# PRU_ICSSG0_PR1_MII_RT_PR1_MII_RT_G_CFG_REGS_G_local register map
Vendor: Texas Instruments
Peripheral module from a debugger description file (folder am65x).
Registers are 32-bit, read-write, reset 0x0 unless marked. A register's access mark holds for its fields unless they carry their own. Offsets are as the file gives them; lines under a group give offsets from that group; [hi:lo] are bit positions; {n}, {i} and the like mark numbered series; 'fields as' and 'values as' point back to an identical list; <NAME> marks a mode.

## PRU_ICSSG0_PR1_MII_RT_PR1_MII_RT_G_CFG_REGS_G
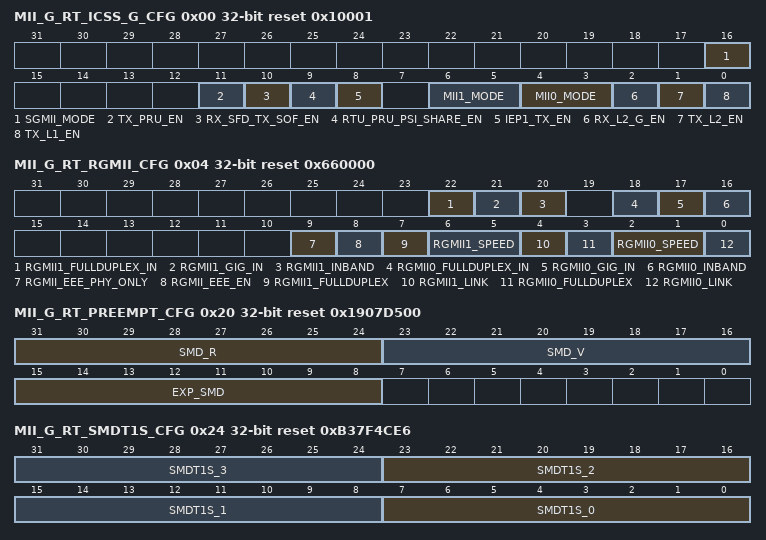
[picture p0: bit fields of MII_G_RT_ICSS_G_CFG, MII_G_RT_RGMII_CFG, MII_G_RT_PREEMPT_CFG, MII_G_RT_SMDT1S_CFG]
0x00 MII_G_RT_ICSS_G_CFG reset 0x10001 — ICSS_G Config
  [16] SGMII_MODE — SGMII MODE 0: Fiber MODE 1: SGMII MODE
  [11] TX_PRU_EN — Enable TX_PRU to gain control of MII TXL2
  [10] RX_SFD_TX_SOF_EN — Enable the remaping of tx_sof to rx_sfd if auto fwd is enable
  [9] RTU_PRU_PSI_SHARE_EN — Enable the sharing of xfr2psi attached to PRU for PRU RTU AND HW FIFO
  [8] IEP1_TX_EN — Enable IEP1 for TX Enable 0: Use IEP0 CMP3_4 1: Use IEP1 CMP3_4
  [6:5] MII1_MODE — MII1 MODE 0: MII 1: RGMII 2: SGMII
  [4:3] MII0_MODE — MII0 MODE 0: MII 1: RGMII 2: SGMII
  [2] RX_L2_G_EN — Enable new RX L2 mode of operation for non-EtherCAT Slave protocols. 0: Disabled 1: Enabled Disable for EtherCAT Slave protocols, enable for all other protocols.
  [1] TX_L2_EN — Enable the TX L2 Fifo 0: Disabled 1: Enabled
  [0] TX_L1_EN — Enable the TX L1 Fifo 0: Disabled 1: Enabled
0x04 MII_G_RT_RGMII_CFG access per field reset 0x660000 — RGMII
  [22] RGMII1_FULLDUPLEX_IN rw — RGMII Fullduplex overide 0: half 1: full
  [21] RGMII1_GIG_IN rw — RGMII GigBit Enable 0: 100 Mbs 1: 1000 Mbs
  [20] RGMII1_INBAND rw — RGMII In BandEnable or Force 0: InBAND is Disabled 1: InBAND Enable
  [18] RGMII0_FULLDUPLEX_IN rw — RGMII Fullduplex overide 0: half 1: full
  [17] RGMII0_GIG_IN rw — RGMII GigBit Enable 0: 100 Mbs 1: 1000 Mbs
  [16] RGMII0_INBAND rw — RGMII In BandEnable or Force 0: InBAND is Disabled 1: InBAND Enable
  [9] RGMII_EEE_PHY_ONLY rw — RGMII Phy Only Low Power 0: disable 1: enable
  [8] RGMII_EEE_EN rw — RGMII Energy Efficient Enable 0: disable 1: enable
  [7] RGMII1_FULLDUPLEX ro — RGMII Fullduplex 0: half duplex 1: full duplex
  [6:5] RGMII1_SPEED ro — RGMII Speed 00: 10Mpbs 01: 100Mpbs 10: 1000 Mpbs
  [4] RGMII1_LINK ro — RGMII Link Status 0: link is down 1: link is up
  [3] RGMII0_FULLDUPLEX ro — RGMII Fullduplex 0: half duplex 1: full duplex
  [2:1] RGMII0_SPEED ro — RGMII Speed 00: 10Mpbs 01: 100Mpbs 10: 1000 Mpbs
  [0] RGMII0_LINK ro — RGMII Link Status 0: link is down 1: link is up
0x08 MII_G_RT_MAC_PRU0_0 — PRU0 MAC (DA3:DA0).
  [31:0] MAC_PRU0_0 — MAC PRU0 DA3:DA0 Used for SAV and DA match
0x0C MII_G_RT_MAC_PRU0_1 — PRU0 MAC (DA5:DA4).
  [15:0] MAC_PRU0_1 — MAC PRU0 DA5:DA4 Used for SAV and DA match
0x10 MII_G_RT_MAC_PRU1_0 — PRU1 MAC (DA3:DA0).
  [31:0] MAC_PRU1_0 — MAC PRU1 DA3:DA0 Used for SAV and DA match
0x14 MII_G_RT_MAC_PRU1_1 — PRU1 MAC (DA5:DA4).
  [15:0] MAC_PRU1_1 — MAC PRU1 DA5:DA4 Used for SAV and DA match
0x18 MII_G_RT_MAC_INTERFACE_0 — MAC Host Interface (DA3:DA0).
  [31:0] MAC_INF_0 — MAC Host interface DA3:DA0 Used for SAV and DA match
0x1C MII_G_RT_MAC_INTERFACE_1 — MAC Host Interface (DA5:DA4).
  [15:0] MAC_INF_1 — MAC Host interface DA 5:DA4 Used for SAV and DA match
0x20 MII_G_RT_PREEMPT_CFG reset 0x1907D500 — Preempt Configuration Register.
  [31:24] SMD_R — Response frame TAG
  [23:16] SMD_V — Verification frame TAG
  [15:8] EXP_SMD — None preemptable frame start, or express frame
0x24 MII_G_RT_SMDT1S_CFG reset 0xB37F4CE6 — SMD Type1S Preemptable Frame Start Configuration.
  [8n+7:8n] SMDT1S_{n} (n=0..3) — SMDT1S{n} pattern
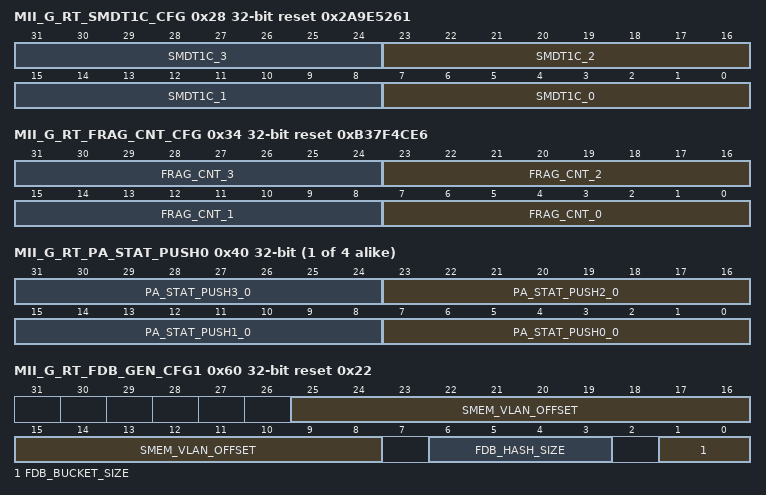
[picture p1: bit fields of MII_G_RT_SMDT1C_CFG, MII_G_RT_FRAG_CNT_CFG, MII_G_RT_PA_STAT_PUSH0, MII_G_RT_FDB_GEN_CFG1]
0x28 MII_G_RT_SMDT1C_CFG reset 0x2A9E5261 — SMD Type1C None Initial Frag Configuration.
  [8n+7:8n] SMDT1C_{n} (n=0..3) — SMDT1C{n} pattern
0x34 MII_G_RT_FRAG_CNT_CFG reset 0xB37F4CE6 — Frag Count Configuration.
  [8n+7:8n] FRAG_CNT_{n} (n=0..3) — FRAG Cnt{n} pattern
{0x40+4i} MII_G_RT_PA_STAT_PUSH{i} (i=0..3) — Pa Stat Push{i}.
  [8n+7:8n] PA_STAT_PUSH{n}_{i} (n=0..3) — pa stat push{n}
0x60 MII_G_RT_FDB_GEN_CFG1 reset 0x22 — FDB Configuration1.
  [25:8] SMEM_VLAN_OFFSET — SMEM VLAN FID table base address
  [6:3] FDB_HASH_SIZE — FDB hash size 0:64 1:128 2:256 3:512 4:1024 5:2048
  [1:0] FDB_BUCKET_SIZE — FDB buket size 0:1 1:2 2:4 3:8
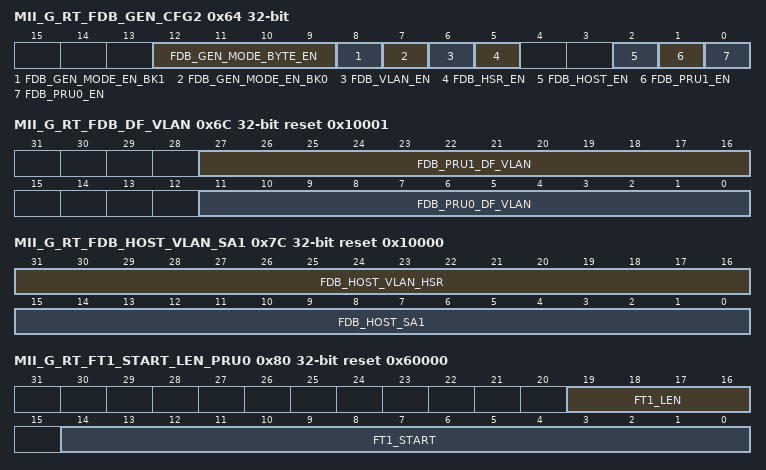
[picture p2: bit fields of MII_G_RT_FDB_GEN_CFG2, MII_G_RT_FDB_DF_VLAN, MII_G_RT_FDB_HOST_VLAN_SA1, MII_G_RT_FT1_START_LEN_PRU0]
0x64 MII_G_RT_FDB_GEN_CFG2 — FDB Configuration2.
  [12:9] FDB_GEN_MODE_BYTE_EN — FDB General Mode Byte compare size 0 = 1 Byte, 15 = 16 Bytes
  [8] FDB_GEN_MODE_EN_BK1 — FDB General Mode Enable Bank1 if set PRU0/PRU1/HOST will get disabled
  [7] FDB_GEN_MODE_EN_BK0 — FDB General Mode Enable Bank0 if set PRU0/PRU1/HOST will get disabled
  [6] FDB_VLAN_EN — FDB Global VLAN Enable
  [5] FDB_HSR_EN — FDB Global HSR Enable note VLAN most be disabled
  [2] FDB_HOST_EN — FDB HOST Enable
  [1] FDB_PRU1_EN — FDB PRU1 Enable
  [0] FDB_PRU0_EN — FDB PRU0 Enable
0x68 MII_G_RT_FDB_GEN_STATUS size not given access not given reset not defined — FDB Status.
0x6C MII_G_RT_FDB_DF_VLAN reset 0x10001 — FDB Default PRU VLAN.
  [27:16] FDB_PRU1_DF_VLAN — FDB Default VLAN for PRU1
  [11:0] FDB_PRU0_DF_VLAN — FDB Default VLAN for PRU0
0x70 MII_G_RT_FDB_HOST_DA0 — FDB HOST DA3:0 Configuration.
  [31:0] FDB_HOST_DA0 — FDB HOST DA3:0
0x74 MII_G_RT_FDB_HOST_DA1 — FDB HOST DA5:4 Configuration.
  [15:0] FDB_HOST_DA1 — FDB HOST DA 5:4
0x78 MII_G_RT_FDB_HOST_SA0 — FDB HOST SA3:0 Configuration.
  [31:0] FDB_HOST_SA0 — FDB HOST SA3:0
0x7C MII_G_RT_FDB_HOST_VLAN_SA1 reset 0x10000 — FDB HOST VLAN SA5:4 Configuration.
  [31:16] FDB_HOST_VLAN_HSR — FDB HOST VLAN[11:0] OR HSR [15:0]
  [15:0] FDB_HOST_SA1 — FDB HOST SA 5:4
0x80 MII_G_RT_FT1_START_LEN_PRU0 reset 0x60000 — Filter1 Start and Length (PRU0).
  [19:16] FT1_LEN — Defines the total number of Bytes Filter1 will check before Valid bit is set
  [14:0] FT1_START — Byte count start for Filter1. Any wrt will clear all Filter1 Status Bits
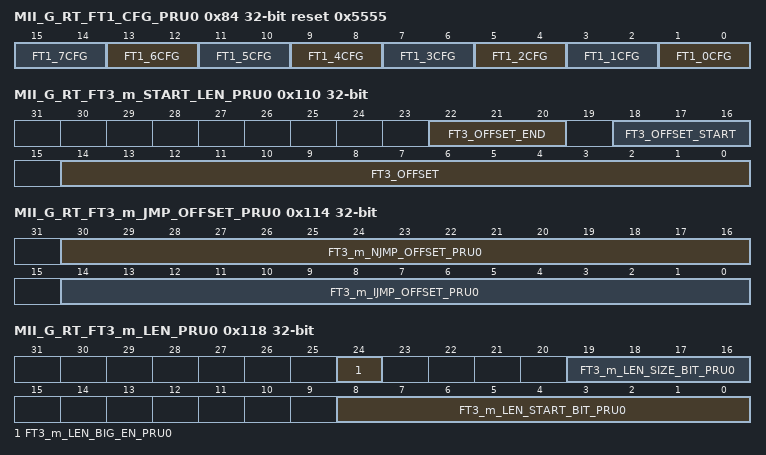
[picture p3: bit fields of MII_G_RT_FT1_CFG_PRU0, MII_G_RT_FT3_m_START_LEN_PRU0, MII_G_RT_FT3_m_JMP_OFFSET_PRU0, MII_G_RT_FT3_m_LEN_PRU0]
0x84 MII_G_RT_FT1_CFG_PRU0 reset 0x5555 — Filter1 Configuration (PRU0).
  [2n+1:2n] FT1_{n}CFG (n=0..7) — 0h = Disabled 1h = Equal 2h = Greater Than 3h = Less Than
0x88 MII_G_RT_FT1_k_DA0_PRU0 — Filter1<k> DA0 (Pru0). Offset = 88h + (k * 10h); where k = 0h to 7h
  [31:0] FT1_k_DA0 — Filter1 DA4:DA1
0x8C MII_G_RT_FT1_k_DA1_PRU0 — Filter1<k> DA1 (PRU0). Offset = 8Ch + (k * 10h); where k = 0h to 7h
  [15:0] FT1_k_DA1 — Filter1 DA6:DA5
0x90 MII_G_RT_FT1_k_DA_MASK0_PRU0 — Filter1<k> DA0 Mask (PRU0). Offset = 90h + (k * 10h); where k = 0h to 7h
  [31:0] FT1_k_DA_MASK0 — Filter1 MDA4:MDA1 set to 1 to mask that bit
0x94 MII_G_RT_FT1_k_DA_MASK1_PRU0 — Filter1<k> DA1 Mask (PRU0). Offset = 94h + (k * 10h); where k = 0h to 7h
  [15:0] FT1_k_DA_MASK1 — Filter1 MDA6:MDA5 set to 1 to mask that bit
0x108 MII_G_RT_FT3_m_START_PRU0 reset 0xC — Filter3 Byte Count Start. Offset = 108h + (m * 20h); where m = 0h to Fh
  [14:0] FT3_START — Byte count start for Filter3. Any wrt will clear all Filter3 Status Bits SW can read to determine next start during Auto
0x10C MII_G_RT_FT3_m_START_AUTO_PRU0 ro — Filter3 Byte Count Start for Auto Skip mode. Offset = 10Ch + (m * 20h); where m = 0h to Fh
  [14:0] FT3_START_AUTO — Byte count start for Auto skip mode
0x110 MII_G_RT_FT3_m_START_LEN_PRU0 — Filter3 Start Offset for PRU0. Offset = 110h + (m * 20h); where m = 0h to Fh
  [22:20] FT3_OFFSET_END — Defines which byte within FT3_[N]P[63:0] to end the compare at set the Valid flag, rule ft3_offset_end &gt;= ft3_offset_start To disable pattern compare set start and end to zero
  [18:16] FT3_OFFSET_START — Defines which byte within FT3_[N]P[63:0] to start the compare
  [14:0] FT3_OFFSET — Determine which byte to start FT3_[N]P[63:0] operation it will start on the next byte after FT3_T completes if set to zero
0x114 MII_G_RT_FT3_m_JMP_OFFSET_PRU0 — Filter3 Jump Offset for PRU0. Offset = 114h + (m * 20h); where m = 0h to Fh
  [30:16] FT3_m_NJMP_OFFSET_PRU0 — Defines the Next Offset to compare when auto arm jump is enabled
  [14:0] FT3_m_IJMP_OFFSET_PRU0 — Defines the Intial Offset to compare when auto arm jump is enabled
0x118 MII_G_RT_FT3_m_LEN_PRU0 — Filter3 Length Offset for PRU0. Offset = 118h + (m * 20h); where m = 0h to Fh
  [24] FT3_m_LEN_BIG_EN_PRU0 — Enable Big Indian on Length
  [19:16] FT3_m_LEN_SIZE_BIT_PRU0 — Defines number of bits to extract the length for the auto skip function
  [8:0] FT3_m_LEN_START_BIT_PRU0 — Defines relative bit offset from the HIT byte location upto 512 bit offset the exraction to determine the on the fly length byte offset
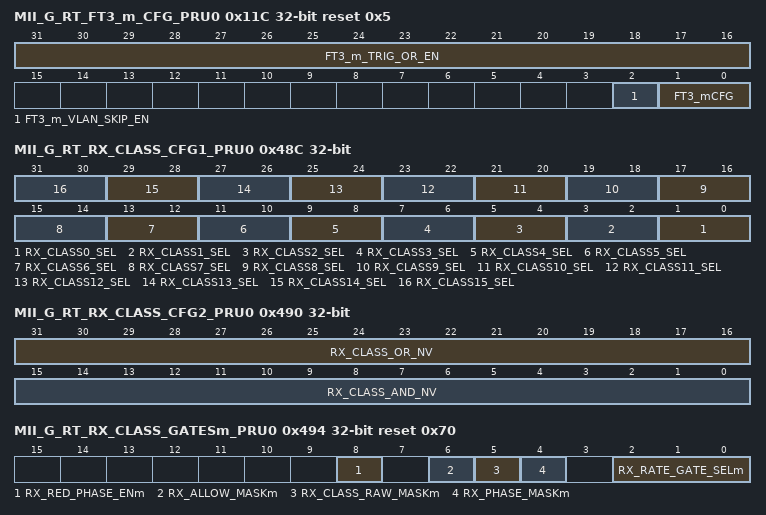
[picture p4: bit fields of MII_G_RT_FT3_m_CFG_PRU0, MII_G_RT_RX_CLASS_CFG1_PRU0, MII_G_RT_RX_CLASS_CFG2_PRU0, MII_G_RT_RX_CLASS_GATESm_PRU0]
0x11C MII_G_RT_FT3_m_CFG_PRU0 reset 0x5 — Filter3 Configuration for PRU0. Offset = 11Ch + (m * 20h); where m = 0h to Fh
  [31:16] FT3_m_TRIG_OR_EN — Trigger ft3 select for auto skip enable, if one or more set the function is enabled note you can not slect the same ft3 only others
  [2] FT3_m_VLAN_SKIP_EN — 0: Disabled 1: Enable
  [1:0] FT3_mCFG — 0: Disabled 1: EQ 2: GT 3: LT
0x120 MII_G_RT_FT3_m_T_PRU0 — Filter3 Type for PRU0. Offset = 120h + (m * 20h); where m = 0h to Fh
  [31:0] FT3_m_T — Filter3 T4:T1 Note if Auto Skip is enabled then Type filter is not enabled
0x124 MII_G_RT_FT3_m_T_MASK_PRU0 — Filter3 Mask for PRU0. Offset = 124h + (m * 20h); where m = 0h to Fh
  [31:0] FT3_m_T_MASK — Filter3 MT4:MT1 Note if Auto Skip is enabled then Type filter is not enabled set to 1 to mask that bit
0x308 MII_G_RT_FT3_m_P0_PRU0 — Filter3 PRU0 (P4:P1). Offset = 308h + (m * 10h); where m = 0h to Fh
  [31:0] FT3_m_P0 — Filter3 P4:P1
0x30C MII_G_RT_FT3_m_P1_PRU0 — Filter3 PRU0 (P8:P5). Offset = 30Ch + (m * 10h); where m = 0h to Fh
  [31:0] FT3_m_P1 — Filter3 P8:P5
0x310 MII_G_RT_FT3_n_P_MASK0_PRU0 — Filter3 Mask0 (MP4:MP1). Offset = 310h + (n * 10h); where n = 0h to Fh
  [31:0] FT3_n_P_MASK0 — Filter3 MP4:MP1 set to 1 to mask that bit
0x314 MII_G_RT_FT3_n_P_MASK1_PRU0 — Filter3 Mask1 (MP8:MP5). Offset = 314h + (n * 10h); where n = 0h to Fh
  [31:0] FT3_n_P_MASK1 — Filter3 MP8:MP5 set to 1 to mask that bit
0x408 MII_G_RT_FT_RX_PTR_PRU0 — RX Current Filter Byte Count (PRU0).
  [31:0] FT_RX_PTR_PRU0 — RX current filter Byte Count
0x40C MII_G_RT_RX_CLASSm_AND_EN_PRU0 — RX Class<m> AND Enable Register. Offset = 40Ch + (m * 8h); where m = 0h to Fh
  [31:0] RX_CLASSm_AND_EN — rx class and enabels
0x410 MII_G_RT_RX_CLASSm_OR_EN_PRU0 — RX Class<m> OR Enable Register. Offset = 410h + (m * 8h); where m = 0h to Fh
  [31:0] RX_CLASSm_OR_EN — rx class or enabels
0x48C MII_G_RT_RX_CLASS_CFG1_PRU0 — RX Class Configuration 1 Register.
  [2n+1:2n] RX_CLASS{n}_SEL (n=0..15) — rx class final term selection 00: OR 01: AND 10: OR AND AND OR 11: OR OR AND
0x490 MII_G_RT_RX_CLASS_CFG2_PRU0 — RX Class Configuration 2 Register.
  [31:16] RX_CLASS_OR_NV — RX class invert OR not invert enable
  [15:0] RX_CLASS_AND_NV — RX class invert AND not invert enable
0x494 MII_G_RT_RX_CLASS_GATESm_PRU0 reset 0x70 — RX Class Gate<m> Configuration PRU0 Register. Offset = 494h + (m * 4h); where m = 0h to Fh
  [8] RX_RED_PHASE_ENm — red phase neable 0: disable 1: enable
  [6] RX_ALLOW_MASKm — allow mask 0: unmask 1: mask
  [5] RX_CLASS_RAW_MASKm — class raw mask 0: unmask 1: mask
  [4] RX_PHASE_MASKm — time phase mask 0: unmask 1: mask
  [2:0] RX_RATE_GATE_SELm — defines which rx_rate will gate rx_class
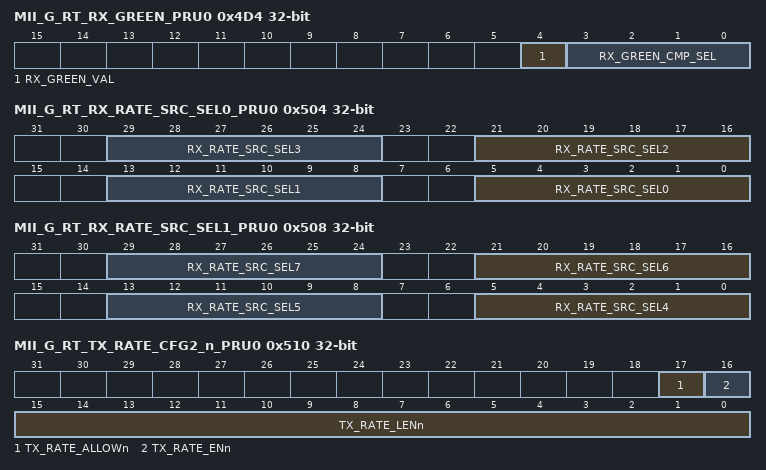
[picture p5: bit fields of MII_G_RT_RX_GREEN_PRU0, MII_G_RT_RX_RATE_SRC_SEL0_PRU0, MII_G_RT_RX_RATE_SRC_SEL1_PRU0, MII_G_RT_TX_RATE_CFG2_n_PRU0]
0x4D4 MII_G_RT_RX_GREEN_PRU0 access per field — RX Green Status PRU0.
  [4] RX_GREEN_VAL ro — 0 RED 1 GREEN status
  [3:0] RX_GREEN_CMP_SEL rw — define which IEP CMP start green
0x4D8 MII_G_RT_SA_HASH_PRU0 — SA Hash Seed PRU0.
  [9:0] SA_HASH_SEED
0x4DC MII_G_RT_CONN_HASH_PRU0 — Connection Hash Seed PRU0.
  [9:0] CONN_HASH_SEED — Connection Hash Seed
0x4E0 MII_G_RT_CONN_HASH_START_PRU0 — Connection Hash Start PRU0.
  [14:0] CONN_HASH_START — Connection Hash Start which 4 Bytes to hash
0x4E4 MII_G_RT_RX_RATE_CFGn_PRU0 — RX Rate Configuration<n> Register. Offset = 4E4h + (n * 4h); where n = 0h to 7h
  [31:0] RX_RATE_CIR_IDLEn — RX Rate Peak Information Rate Idle Increment Value - The number added to the PIR counter every clock cycle including EOF. The PIR counter is disabled with a zero value and packets will not be marked RED
0x504 MII_G_RT_RX_RATE_SRC_SEL0_PRU0 — RX Rate Source Select0.
  [8n+5:8n] RX_RATE_SRC_SEL{n} (n=0..3) — Map which filter/flag/class hit that rate logic uses, see table for mapping
0x508 MII_G_RT_RX_RATE_SRC_SEL1_PRU0 — RX Rate Source Select1.
  [8n-27:8n-32] RX_RATE_SRC_SEL{n} (n=4..7) — Map which filter/flag/class hit that rate logic uses, see table for mapping
0x50C MII_G_RT_TX_RATE_CFG1_n_PRU0 — TX Rate Configuration1 Registe. Offset = 50Ch + (n * 8h); where n = 0h to 7h
  [31:0] TX_RATE_CIR_IDLEn — TX Rate Peak Information Rate Idle Increment Value - The number added to the PIR counter every clock cycle including EOF. The PIR counter is disabled with a zero value and packets will not be marked RED
0x510 MII_G_RT_TX_RATE_CFG2_n_PRU0 access per field — TX Rate Configuration2 Register. Offset = 510h + (n * 8h); where n = 0h to 7h
  [17] TX_RATE_ALLOWn ro — TX Rate Pkt Enable
  [16] TX_RATE_ENn rw — TX Rate Pkt Enable
  [15:0] TX_RATE_LENn rw — TX Rate Pkt Length
0x54C MII_G_RT_RX_STAT_GOOD_PRU0 — RX Good Frame Count (PRU0).
  [31:0] RX_GOOD_FRM_CNT — RX Good Frame Count Inc on none min err max err crc err odd err, Wrt subtracts
0x550 MII_G_RT_RX_STAT_BC_PRU0 — RX BC Frame Count (PRU0).
  [15:0] RX_BC_FRM_CNT — RX BC Frame Count Inc on BC type, Wrt subtracts
0x554 MII_G_RT_RX_STAT_MC_PRU0 — RX MC Frame Count (PRU0).
  [15:0] RX_MC_FRM_CNT — RX MC Frame Count Inc on MC type, Wrt subtracts
0x558 MII_G_RT_RX_STAT_CRC_ERR_PRU0 — RX CRC Error Frame Count (PRU0).
  [15:0] RX_CRC_ERR_FRM_CNT — RX CRC Err Frame Count Inc on crc err, Wrt subtracts
0x55C MII_G_RT_RX_STAT_MII_ERR_PRU0 — RX MII Error Frame Count (PRU0).
  [15:0] RX_MII_ERR_FRM_CNT — RX MII Err Frame Count Inc on mii sgmii rgmii err, Wrt subtracts
0x560 MII_G_RT_RX_STAT_ODD_ERR_PRU0 — RX Odd Nibble Frame Count (PRU0).
  [15:0] RX_ODD_ERR_FRM_CNT — RX Odd Nibble Frame Count Inc on odd nibble mii, Wrt subtracts
0x564 MII_G_RT_RX_STAT_MAX_SIZE_PRU0 reset 0x7D0 — RX Max Size Frame Count (PRU0).
  [15:0] RX_MAX_SIZE_FRM — RX MAX Size Frame Count Limit
0x568 MII_G_RT_RX_STAT_MAX_ERR_PRU0 — RX Max Size Error Frame Count (PRU0).
  [15:0] RX_MAX_ERR_FRM_CNT — RX MAX Size Err Frame Count Inc if &gt; than Limit, Wrt subtracts
0x56C MII_G_RT_RX_STAT_MIN_SIZE_PRU0 reset 0x40 — RX Min Size Frame Count (PRU0).
  [15:0] RX_MIN_SIZE_FRM — RX MIN Size Frame Limit
0x570 MII_G_RT_RX_STAT_MIN_ERR_PRU0 — RX Min Size Error Frame Count (PRU0).
  [15:0] RX_MIN_ERR_FRM_CNT — RX MIN Size Frame Count Inc if &lt; than limit, Wrt subtracts
0x574 MII_G_RT_RX_STAT_OVERRUN_ERR_PRU0 — RX Overrun Frame Count (PRU0).
  [15:0] RX_OVERRUN_ERR_FRM_CNT — RX L1 FIFO overflow Frame Count. Inc on overflow event, Wrt subtracts
0x578 MII_G_RT_RX_STAT_CLASSm_HIT_PRU0 — RX Class<m> Hit. Offset = 578h + (n * 4h); where m = 0h to Fh
  [31:0] RX_STAT_CLASSm_PRU0 — RX Class&lt;m&gt; Hit Count (where m = 0 to 15). Wrt subtracts
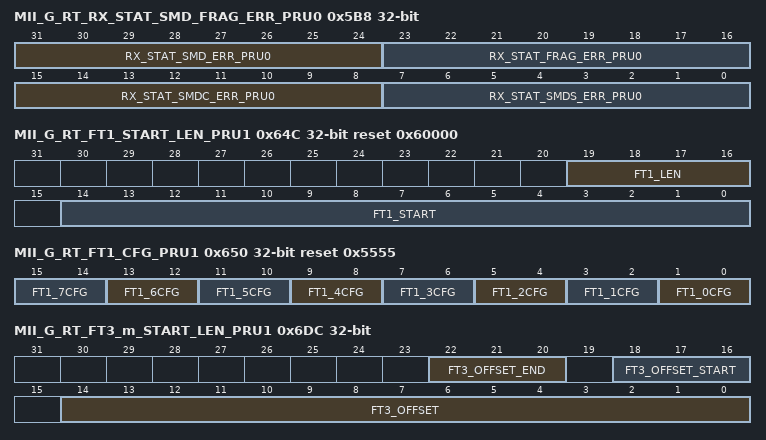
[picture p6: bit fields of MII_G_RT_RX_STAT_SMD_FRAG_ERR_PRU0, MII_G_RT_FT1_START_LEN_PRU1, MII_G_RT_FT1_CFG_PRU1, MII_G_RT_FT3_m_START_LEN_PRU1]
0x5B8 MII_G_RT_RX_STAT_SMD_FRAG_ERR_PRU0 — RX SMD Frag Error Count PRU0.
  [31:24] RX_STAT_SMD_ERR_PRU0 — RX SMDS Error Count, Inc when first none 0x55 does not match any valid SMD, Wrt subtracts
  [23:16] RX_STAT_FRAG_ERR_PRU0 — RX Frag_Cnt Seq Error Count, Wrt subtracts
  [15:8] RX_STAT_SMDC_ERR_PRU0 — RX SMDCx Seq Error Count, Wrt subtracts
  [7:0] RX_STAT_SMDS_ERR_PRU0 — RX SMDSx Seq Error Count, Wrt subtracts
0x5BC MII_G_RT_RX_STAT_BKT1_SIZE_PRU0 reset 0x40 — RX Bucket1 Size Configuration (PRU0).
  [13:0] RX_STAT_BKT1_SIZE — RX Bucket1 Byte Size
0x5C0 MII_G_RT_RX_STAT_BKT2_SIZE_PRU0 reset 0x80 — RX Bucket2 Size Configuration (PRU0).
  [13:0] RX_STAT_BKT2_SIZE — RX Bucket2 Byte Size
0x5C4 MII_G_RT_RX_STAT_BKT3_SIZE_PRU0 reset 0x100 — RX Bucket3 Size Configuration (PRU0).
  [13:0] RX_STAT_BKT3_SIZE — RX Bucket3 Byte Size
0x5C8 MII_G_RT_RX_STAT_BKT4_SIZE_PRU0 reset 0x200 — RX Bucket4 Size Configuration (PRU0).
  [13:0] RX_STAT_BKT4_SIZE — RX Bucket4 Byte Size
0x5CC MII_G_RT_RX_STAT_64_PRU0 — RX 64B Sized Frame Count (PRU0).
  [15:0] RX_64_FRM_CNT — RX 64Byte Frame Count Inc if 64B size
0x5D0 MII_G_RT_RX_STAT_BKT1_PRU0 — RX Bucket1 Sized Frame Count (PRU0).
  [15:0] RX_STAT_BKT1 — RX Bucket1 Frame Count Inc if &lt;= than Bucket1 Byte Size
{0x5CC+4i} MII_G_RT_RX_STAT_BKT{i}_PRU0 (i=2..4) — RX Bucket{i} Sized Frame Count (PRU0).
  [15:0] RX_STAT_BKT{i} — RX Bucket{i} Frame Count Inc if &lt;= than Bucket{i} Byte Size and if &gt; than Bucket{i-1} Byte Size
0x5E0 MII_G_RT_RX_STAT_BKT5_PRU0 — RX Bucket5 Sized Frame Count (PRU0).
  [15:0] RX_STAT_BKT5 — RX Bucket5 Frame Count Inc if &gt; than Bucket4 Byte Size
0x5E4 MII_G_RT_RX_STAT_TOTAL_BYTES_PRU0 — RX Total Byte Count (PRU0).
  [31:0] RX_STAT_TOTAL_BYTES_PRU — RX Total Byte Count
0x5E8 MII_G_RT_RXTX_STAT_TOTAL_BYTES_PRU0 — RX TX Total Byte Count (PRU0).
  [31:0] RXTX_STAT_TOTAL_BYTES_PRU — RX and TX Total Byte Count
0x5EC MII_G_RT_TX_STAT_GOOD_PORT0 — TX Good Frame Count Port0.
  [31:0] TX_GOOD_FRM_CNT — TX Good Frame Count Inc if no min size err max size err or mii odd nibble
0x5F0 MII_G_RT_TX_STAT_BC_PORT0 — TX BC Frame Count Port0.
  [15:0] TX_BC_FRM_CNT — TX BC Frame Count Inc if BC
0x5F4 MII_G_RT_TX_STAT_MC_PORT0 — TX MC Frame Count Port0.
  [15:0] TX_MC_FRM_CNT — TX MC Frame Count. Inc if MC
0x5F8 MII_G_RT_TX_STAT_ODD_ERR_PORT0 — TX Odd Nibble Frame Count Port0.
  [15:0] TX_ODD_ERR_FRM_CNT — TX Odd Nibble Frame Count Inc if mii odd nibble
0x5FC MII_G_RT_TX_STAT_UNDERFLOW_ERR_PORT0 — TX Under Flow Error Count Port0.
  [15:0] TX_UNDERFLOW_CNT — TX MAX Underflow Error Cnt
0x600 MII_G_RT_TX_STAT_MAX_SIZE_PORT0 reset 0x7D0 — TX Max Size Frame Port0.
  [15:0] TX_MAX_SIZE_FRM — TX MAX Size Frame Count Limit
0x604 MII_G_RT_TX_STAT_MAX_ERR_PORT0 — TX Max Size Error Frame Count Port0.
  [15:0] TX_MAX_ERR_FRM_CNT — TX MAX Size Err Frame Count Inc if &gt; max Limit
0x608 MII_G_RT_TX_STAT_MIN_SIZE_PORT0 reset 0x40 — TX Min Size Frame Port0.
  [15:0] TX_MIN_SIZE_FRM — TX MIN Size Frame Count Limit
0x60C MII_G_RT_TX_STAT_MIN_ERR_PORT0 — TX Min Size ErrorFrame Count Port0.
  [15:0] TX_MIN_ERR_FRM_CNT — TX MIN Size Err Frame Count Inc if &lt; min Limit
0x610 MII_G_RT_TX_STAT_BKT1_SIZE_PORT0 reset 0x40 — TX Bucket1 Size Configuration Port0.
  [13:0] TX_STAT_BKT1_SIZE — TX Bucket1 Byte Size
0x614 MII_G_RT_TX_STAT_BKT2_SIZE_PORT0 reset 0x80 — TX Bucket2 Size Configuration Port0.
  [13:0] TX_STAT_BKT2_SIZE — TX Bucket2 Byte Size
0x618 MII_G_RT_TX_STAT_BKT3_SIZE_PORT0 reset 0x100 — TX Bucket3 Size Configuration Port0.
  [13:0] TX_STAT_BKT3_SIZE — TX Bucket3 Byte Size
0x61C MII_G_RT_TX_STAT_BKT4_SIZE_PORT0 reset 0x200 — TX Bucket4 Size Configuration Port0.
  [13:0] TX_STAT_BKT4_SIZE — TX Bucket4 Byte Size
0x620 MII_G_RT_TX_STAT_64_PORT0 — TX 64B Sized Frame Count Port0.
  [15:0] TX_64_FRM_CNT — TX 64Byte Frame Count. Inc if 64B
0x624 MII_G_RT_TX_STAT_BKT1_PORT0 — TX Bucket1 Sized Frame Count Port0.
  [15:0] TX_STAT_BKT1 — TX Bucket1 Inc if &lt;= than Bucket1
{0x620+4i} MII_G_RT_TX_STAT_BKT{i}_PORT0 (i=2..4) — TX Bucket{i} Sized Frame Count Port0.
  [15:0] TX_STAT_BKT{i} — TX Bucket{i} Inc if &lt;= than Bucket{i} Byte Size and if &gt; than Bucket{i-1} Byte Size
0x634 MII_G_RT_TX_STAT_BKT5_PORT0 — TX Bucket5 Sized Frame Count Port0.
  [15:0] TX_STAT_BKT5 — TX Bucket5 Inc if &gt; than Bucket4 Byte Size
0x638 MII_G_RT_TX_STAT_TOTAL_BYTES_PORT0 — TX Total Byte Count Port0.
  [31:0] TX_TOTAL_STAT_BYTES_PORT — TX Total Byte Count of all Frames
0x63C MII_G_RT_TX_HSR_TAG_PORT0 reset 0x892F — TX HSR TAG Port0.
  [31:0] TX_HSR_TAG — HSR TAG
0x640 MII_G_RT_TX_HSR_SEQ_PORT0 — TX HSR Seq Port0.
  [15:0] TX_HSR_SEQ — HSR Seq count. It will incr for every HSR type
0x644 MII_G_RT_TX_VLAN_TYPE_TAG_PORT0 reset 0x81 — TX VLAN Type TAG Port0.
  [15:0] TX_VLAN_TYPE_TAG — TX VLAN Type Tag, match to enable VLAN removal
0x648 MII_G_RT_TX_VLAN_INS_TAG_PORT0 reset 0x1 — TX VLAN Insertion TAG Port0.
  [31:0] TX_VLAN_INS_TAG — TX VLAN Insertion
0x64C MII_G_RT_FT1_START_LEN_PRU1 reset 0x60000 — Filter1 Start and Length (PRU1).
  fields as MII_G_RT_FT1_START_LEN_PRU0
0x650 MII_G_RT_FT1_CFG_PRU1 reset 0x5555 — Filter1 Configuration (PRU1).
  fields as MII_G_RT_FT1_CFG_PRU0
0x654 MII_G_RT_FT1_k_DA0_PRU1 — Filter1<k> DA0 (PRU1). Offset = 654h + (k * 10h); where k = 0h to 7h
  [31:0] FT1_k_DA0 — Filter1 DA4:DA1
0x658 MII_G_RT_FT1_k_DA1_PRU1 — Filter1<k> DA1 (PRU1). Offset = 658h + (k * 10h); where k = 0h to 7h
  [15:0] FT1_k_DA1 — Filter1 DA6:DA5
0x65C MII_G_RT_FT1_k_DA_MASK0_PRU1 — Filter1<k> DA0 Mask (PRU1). Offset = 65Ch + (k * 10h); where k = 0h to 7h
  [31:0] FT1_k_DA_MASK0 — Filter1 MDA4:MDA1 set to 1 to mask that bit
0x660 MII_G_RT_FT1_k_DA_MASK1_PRU1 — Filter1<k> DA1 Mask (PRU1). Offset = 660h + (k * 10h); where k = 0h to 7h
  [15:0] FT1_k_DA_MASK1 — Filter1 MDA6:MDA5 set to 1 to mask that bit
0x6D4 MII_G_RT_FT3_m_START_PRU1 reset 0xC — Filter3<m> Start (PRU1). Offset = 6D4h + (m * 20h); where m = 0h to Fh
  fields as MII_G_RT_FT3_m_START_PRU0
0x6D8 MII_G_RT_FT3_m_START_AUTO_PRU1 ro — Filter3<m> Start Auto (PRU1). Offset = 6D8h + (m * 20h); where m = 0h to Fh
  [14:0] FT3_START_AUTO — Byte count start for Auto skip mode
0x6DC MII_G_RT_FT3_m_START_LEN_PRU1 — Filter3<m> Start offset (PRU1). Offset = 6DCh + (m * 20h); where m = 0h to Fh
  fields as MII_G_RT_FT3_m_START_LEN_PRU0
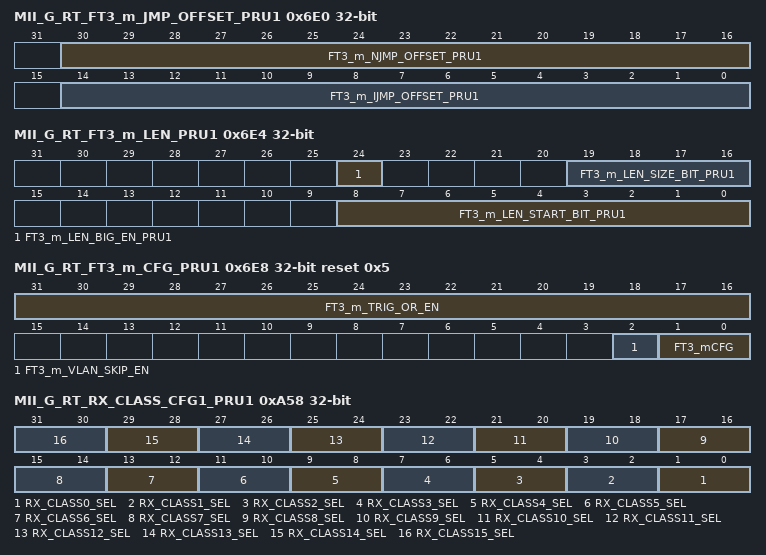
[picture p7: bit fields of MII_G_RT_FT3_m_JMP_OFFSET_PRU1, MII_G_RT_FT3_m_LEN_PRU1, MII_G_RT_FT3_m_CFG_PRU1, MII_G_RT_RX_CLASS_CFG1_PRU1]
0x6E0 MII_G_RT_FT3_m_JMP_OFFSET_PRU1 — Filter3<m> Jmp offset (PRU1). Offset = 6E0h + (m * 20h); where m = 0h to Fh
  [30:16] FT3_m_NJMP_OFFSET_PRU1 — Defines the Next Offset to compare when auto arm jump is enabled
  [14:0] FT3_m_IJMP_OFFSET_PRU1 — Defines the Intial Offset to compare when auto arm jump is enabled
0x6E4 MII_G_RT_FT3_m_LEN_PRU1 — Filter3 Length Offset for (PRU1). Offset = 6E4h + (m * 20h); where m = 0h to Fh
  [24] FT3_m_LEN_BIG_EN_PRU1 — Enable Big Indian on Length
  [19:16] FT3_m_LEN_SIZE_BIT_PRU1 — Defines number of bits to extract the length for the auto skip function
  [8:0] FT3_m_LEN_START_BIT_PRU1 — Defines relative bit offset from the HIT byte location upto 512 bit offset the exraction to determine the on the fly length byte offset
0x6E8 MII_G_RT_FT3_m_CFG_PRU1 reset 0x5 — Filter3<m> Configuration (PRU1). Offset = 6E8h + (m * 20h); where m = 0h to Fh
  fields as MII_G_RT_FT3_m_CFG_PRU0
0x6EC MII_G_RT_FT3_m_T_PRU1 — Filter3<m> T (PRU1). Offset = 6ECh + (m * 20h); where m = 0h to Fh
  fields as MII_G_RT_FT3_m_T_PRU0
0x6F0 MII_G_RT_FT3_m_T_MASK_PRU1 — Filter3<m> T Mask (PRU1). Offset = 6F0h + (m * 20h); where m = 0h to Fh
  fields as MII_G_RT_FT3_m_T_MASK_PRU0
0x8D4 MII_G_RT_FT3_m_P0_PRU1 — Filter3<m> P0 (PRU1). Offset = 8D4h + (m * 10h); where m = 0h to Fh
  [31:0] FT3_m_P0 — Filter3 P4:P1
0x8D8 MII_G_RT_FT3_m_P1_PRU1 — Filter3<m> P1 (PRU1). Offset = 8D8h + (m * 10h); where m = 0h to Fh
  [31:0] FT3_m_P1 — Filter3 P8:P5
0x8DC MII_G_RT_FT3_m_P_MASK0_PRU1 — Filter3<m> P Mask0 (PRU1). Offset = 8DCh + (m * 10h); where m = 0h to Fh
  [31:0] FT3_m_P_MASK0 — Filter3 MP4:MP1 set to 1 to mask that bit
0x8E0 MII_G_RT_FT3_m_P_MASK1_PRU1 — Filter3<m> P Mask1 (PRU1). Offset = 8E0h + (m * 10h); where m = 0h to Fh
  [31:0] FT3_m_P_MASK1 — Filter3 MP8:MP5 set to 1 to mask that bit
0x9D4 MII_G_RT_FT_RX_PTR_PRU1 — Filter Byte Count (PRU1).
  [31:0] FT_RX_PTR_PRU1 — RX current filter Byte Count
0x9D8 MII_G_RT_RX_CLASSm_AND_EN_PRU1 — RX Class<m> AND Enable (PRU1). Offset = 9D8h + (m * 8h); where m = 0h to Fh
  [31:0] RX_CLASSm_AND_EN — RX class AND enabels.
0x9DC MII_G_RT_RX_CLASSm_OR_EN_PRU1 — RX Class<m> OR Enable (PRU1). Offset = 9DCh + (m * 8h); where m = 0h to Fh
  [31:0] RX_CLASSm_OR_EN — RX class OR enabels.
0xA58 MII_G_RT_RX_CLASS_CFG1_PRU1 — RX Class Configuration 1 Register.
  fields as MII_G_RT_RX_CLASS_CFG1_PRU0
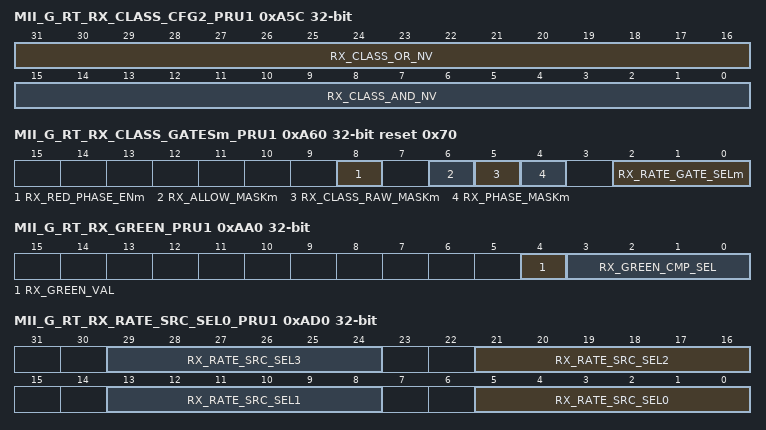
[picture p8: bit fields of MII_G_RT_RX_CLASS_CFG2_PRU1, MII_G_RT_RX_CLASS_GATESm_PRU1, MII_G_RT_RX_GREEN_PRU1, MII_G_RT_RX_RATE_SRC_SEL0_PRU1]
0xA5C MII_G_RT_RX_CLASS_CFG2_PRU1 — RX Class Configuration 2 Register.
  [31:16] RX_CLASS_OR_NV — RX class or nv enable
  [15:0] RX_CLASS_AND_NV — RX class and nv enable
0xA60 MII_G_RT_RX_CLASS_GATESm_PRU1 reset 0x70 — RX Class Gate Configuration PRU1 Register. Offset = A60h + (m * 4h); where m = 0h to Fh
  fields as MII_G_RT_RX_CLASS_GATESm_PRU0
0xAA0 MII_G_RT_RX_GREEN_PRU1 access per field — RX Green Status PRU1.
  fields as MII_G_RT_RX_GREEN_PRU0
0xAA4 MII_G_RT_SA_HASH_PRU1 — SA Hash Seed PRU1.
  [9:0] SA_HASH_SEED
0xAA8 MII_G_RT_CONN_HASH_PRU1 — Connection Hash Seed PRU1.
  [9:0] CONN_HASH_SEED — Connection Hash Seed
0xAAC MII_G_RT_CONN_HASH_START_PRU1 — Connection Hash Start PRU1.
  [14:0] CONN_HASH_START — Connection Hash Start which 4 Bytes to hash
0xAB0 MII_G_RT_RX_RATE_CFGn_PRU1 — RX Rate Configuration Register. Offset = AB0h + (n * 4h); where n = 0h to 7h
  fields as MII_G_RT_RX_RATE_CFGn_PRU0
0xAD0 MII_G_RT_RX_RATE_SRC_SEL0_PRU1 — RX Rate Source Select0.
  fields as MII_G_RT_RX_RATE_SRC_SEL0_PRU0
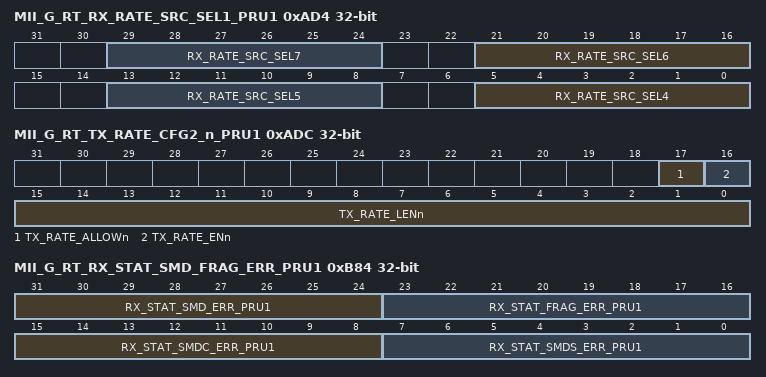
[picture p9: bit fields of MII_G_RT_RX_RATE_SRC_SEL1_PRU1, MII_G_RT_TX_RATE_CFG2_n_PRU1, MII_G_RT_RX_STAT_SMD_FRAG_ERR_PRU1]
0xAD4 MII_G_RT_RX_RATE_SRC_SEL1_PRU1 — RX Rate Source Select1.
  fields as MII_G_RT_RX_RATE_SRC_SEL1_PRU0
0xAD8 MII_G_RT_TX_RATE_CFG1_n_PRU1 — TX Rate Configuration 1 Register. Offset = AD8h + (n * 8h); where n = 0h to 7h
  fields as MII_G_RT_TX_RATE_CFG1_n_PRU0
0xADC MII_G_RT_TX_RATE_CFG2_n_PRU1 access per field — TX Rate Configuration 2 Register. Offset = ADCh + (n * 8h); where n = 0h to 7h
  fields as MII_G_RT_TX_RATE_CFG2_n_PRU0
0xB18 MII_G_RT_RX_STAT_GOOD_PRU1 — RX Good Frame Count (PRU1).
  [31:0] RX_GOOD_FRM_CNT — RX Good Frame Count. Inc on none min err max err crc err odd err, Wrt subtracts
0xB1C MII_G_RT_RX_STAT_BC_PRU1 — RX BC Frame Count (PRU1).
  fields as MII_G_RT_RX_STAT_BC_PRU0
0xB20 MII_G_RT_RX_STAT_MC_PRU1 — RX MC Frame Count (PRU1).
  fields as MII_G_RT_RX_STAT_MC_PRU0
0xB24 MII_G_RT_RX_STAT_CRC_ERR_PRU1 — RX CRC Error Frame Count (PRU1).
  fields as MII_G_RT_RX_STAT_CRC_ERR_PRU0
0xB28 MII_G_RT_RX_STAT_MII_ERR_PRU1 — RX MII Error Frame Count (PRU1).
  fields as MII_G_RT_RX_STAT_MII_ERR_PRU0
0xB2C MII_G_RT_RX_STAT_ODD_ERR_PRU1 — RX Odd Nibble Frame Count (PRU1).
  fields as MII_G_RT_RX_STAT_ODD_ERR_PRU0
0xB30 MII_G_RT_RX_STAT_MAX_SIZE_PRU1 reset 0x7D0 — RX Max Size Frame (PRU1).
  [15:0] RX_MAX_SIZE_FRM — RX MAX Size Frame Count Limit
0xB34 MII_G_RT_RX_STAT_MAX_ERR_PRU1 — RX Max Size Error Frame Count (PRU1).
  fields as MII_G_RT_RX_STAT_MAX_ERR_PRU0
0xB38 MII_G_RT_RX_STAT_MIN_SIZE_PRU1 reset 0x40 — RX Min Size Frame (PRU1).
  [15:0] RX_MIN_SIZE_FRM — RX MIN Size Frame Limit
0xB3C MII_G_RT_RX_STAT_MIN_ERR_PRU1 — RX Min Size Error Frame Count (PRU1).
  fields as MII_G_RT_RX_STAT_MIN_ERR_PRU0
0xB40 MII_G_RT_RX_STAT_OVERRUN_ERR_PRU1 — RX Overrun Frame Count (PRU1).
  [15:0] RX_OVERRUN_ERR_FRM_CNT — RX L1 FIFO overflow Frame Count Inc on overflow event, Wrt subtracts
0xB44 MII_G_RT_RX_STAT_CLASSm_HIT_PRU1 — RX Class<m>. Offset = B44h + (m * 4h); where m = 0h to Fh
  [31:0] RX_STAT_CLASSm_PRU1 — RX Class&lt;m&gt; Hit Count (where m = 0 to 15). Wrt subtracts
0xB84 MII_G_RT_RX_STAT_SMD_FRAG_ERR_PRU1 — RX SMD Frag Error Count (PRU1).
  [31:24] RX_STAT_SMD_ERR_PRU1 — RX SMDS Error Count, Inc when first none 0x55 does not match any valid SMD, Wrt subtracts
  [23:16] RX_STAT_FRAG_ERR_PRU1 — RX Frag_Cnt Seq Error Count, Wrt subtracts
  [15:8] RX_STAT_SMDC_ERR_PRU1 — RX SMDCx Seq Error Count, Wrt subtracts
  [7:0] RX_STAT_SMDS_ERR_PRU1 — RX SMDSx Seq Error Count, Wrt subtracts
0xB88 MII_G_RT_RX_STAT_BKT1_SIZE_PRU1 reset 0x40 — RX Bucket1 Size Configuration (PRU1).
  [13:0] RX_STAT_BKT1_SIZE — RX Bucket1 Byte Size
0xB8C MII_G_RT_RX_STAT_BKT2_SIZE_PRU1 reset 0x80 — RX Bucket2 Size Configuration (PRU1).
  [13:0] RX_STAT_BKT2_SIZE — RX Bucket2 Byte Size
0xB90 MII_G_RT_RX_STAT_BKT3_SIZE_PRU1 reset 0x100 — RX Bucket3 Size Configuration (PRU1).
  [13:0] RX_STAT_BKT3_SIZE — RX Bucket3 Byte Size
0xB94 MII_G_RT_RX_STAT_BKT4_SIZE_PRU1 reset 0x200 — RX Bucket4 Size Configuration (PRU1).
  [13:0] RX_STAT_BKT4_SIZE — RX Bucket4 Byte Size
0xB98 MII_G_RT_RX_STAT_64_PRU1 — RX 64B Sized Frame Count (PRU1).
  [15:0] RX_64_FRM_CNT — RX 64Byte Frame Count Inc if 64B size
0xB9C MII_G_RT_RX_STAT_BKT1_PRU1 — RX Bucket1 Sized Frame Count (PRU1).
  fields as MII_G_RT_RX_STAT_BKT1_PRU0
{0xB98+4i} MII_G_RT_RX_STAT_BKT{i}_PRU1 (i=2..4) — RX Bucket{i} Sized Frame Count (PRU1).
  fields as MII_G_RT_RX_STAT_BKT2_PRU0
0xBAC MII_G_RT_RX_STAT_BKT5_PRU1 — RX Bucket5 Sized Frame Count (PRU1).
  fields as MII_G_RT_RX_STAT_BKT5_PRU0
0xBB0 MII_G_RT_RX_STAT_TOTAL_BYTES_PRU1 — RX Total Byte Count (PRU1).
  [31:0] RX_STAT_TOTAL_BYTES_PRU — RX Total Byte Count
0xBB4 MII_G_RT_RXTX_STAT_TOTAL_BYTES_PRU1 — RX TX Total Byte Count (PRU1).
  [31:0] RXTX_STAT_TOTAL_BYTES_PRU — RX and TX Total Byte Count
0xBB8 MII_G_RT_TX_STAT_GOOD_PORT1 — TX Good Frame Count Port1.
  fields as MII_G_RT_TX_STAT_GOOD_PORT0
0xBBC MII_G_RT_TX_STAT_BC_PORT1 — TX BC Frame Count Port1.
  [15:0] TX_BC_FRM_CNT — TX BC Frame Count Inc if BC
0xBC0 MII_G_RT_TX_STAT_MC_PORT1 — TX MC Frame Count Port1.
  [15:0] TX_MC_FRM_CNT — TX MC Frame Count Inc if MC
0xBC4 MII_G_RT_TX_STAT_ODD_ERR_PORT1 — TX Odd Nibble Frame Count Port1.
  fields as MII_G_RT_TX_STAT_ODD_ERR_PORT0
0xBC8 MII_G_RT_TX_STAT_UNDERFLOW_ERR_PORT1 — TX Under Flow Error Count Port1.
  [15:0] TX_UNDERFLOW_CNT — TX MAX Underflow Error Cnt
0xBCC MII_G_RT_TX_STAT_MAX_SIZE_PORT1 reset 0x7D0 — TX Max Size Frame Port1.
  [15:0] TX_MAX_SIZE_FRM — TX MAX Size Frame Count Limit
0xBD0 MII_G_RT_TX_STAT_MAX_ERR_PORT1 — TX Max Size Error Frame Count Port1.
  fields as MII_G_RT_TX_STAT_MAX_ERR_PORT0
0xBD4 MII_G_RT_TX_STAT_MIN_SIZE_PORT1 reset 0x40 — TX Min Size Frame Port1.
  [15:0] TX_MIN_SIZE_FRM — TX MIN Size Frame Count Limit
0xBD8 MII_G_RT_TX_STAT_MIN_ERR_PORT1 — TX Min Size Error Frame Count Port1.
  fields as MII_G_RT_TX_STAT_MIN_ERR_PORT0
0xBDC MII_G_RT_TX_STAT_BKT1_SIZE_PORT1 reset 0x40 — TX Bucket1 Size Configuration Port1.
  [13:0] TX_STAT_BKT1_SIZE — TX Bucket1 Byte Size
0xBE0 MII_G_RT_TX_STAT_BKT2_SIZE_PORT1 reset 0x80 — TX Bucket2 Size Configuration Port1.
  [13:0] TX_STAT_BKT2_SIZE — TX Bucket2 Byte Size
0xBE4 MII_G_RT_TX_STAT_BKT3_SIZE_PORT1 reset 0x100 — TX Bucket3 Size Configuration Port1.
  [13:0] TX_STAT_BKT3_SIZE — TX Bucket3 Byte Size
0xBE8 MII_G_RT_TX_STAT_BKT4_SIZE_PORT1 reset 0x200 — TX Bucket4 Size Configuration Port1.
  [13:0] TX_STAT_BKT4_SIZE — TX Bucket4 Byte Size
0xBEC MII_G_RT_TX_STAT_64_PORT1 — TX 64B Sized Frame Count Port1.
  [15:0] TX_64_FRM_CNT — TX 64Byte Frame Count Inc if 64B
0xBF0 MII_G_RT_TX_STAT_BKT1_PORT1 — TX Bucket1 Sized Frame Count Port1.
  [15:0] TX_STAT_BKT1 — TX Bucket1 Inc if &lt;= than Bucket1
{0xBEC+4i} MII_G_RT_TX_STAT_BKT{i}_PORT1 (i=2..4) — TX Bucket{i} Sized Frame Count Port1.
  fields as MII_G_RT_TX_STAT_BKT2_PORT0
0xC00 MII_G_RT_TX_STAT_BKT5_PORT1 — TX Bucket5 Sized Frame Count Port1.
  [15:0] TX_STAT_BKT5 — TX Bucket5 Inc if &gt; than Bucket4 Byte Size
0xC04 MII_G_RT_TX_STAT_TOTAL_BYTES_PORT1 — TX Total Byte Count Port1.
  [31:0] TX_TOTAL_STAT_BYTES_PORT — TX Total Byte Count of all Frames
0xC08 MII_G_RT_TX_HSR_TAG_PORT1 reset 0x892F — TX HSR TAG Port1.
  [31:0] TX_HSR_TAG — HSR TAG
0xC0C MII_G_RT_TX_HSR_SEQ_PORT1 — TX HSR Seq Port1.
  [15:0] TX_HSR_SEQ — HSR Seq count. It will incr for every HSR type
0xC10 MII_G_RT_TX_VLAN_TYPE_TAG_PORT1 reset 0x81 — TX VLAN Type TAG Port1.
  fields as MII_G_RT_TX_VLAN_TYPE_TAG_PORT0
0xC14 MII_G_RT_TX_VLAN_INS_TAG_PORT1 reset 0x1 — TX VLAN Insertion TAG Port1.
  [31:0] TX_VLAN_INS_TAG — TX VLAN Insertion
0xD00 MII_G_RT_QUEUEk — Queue<k>. Offset = D00h + (k * 4h); where k = 0h to 3Fh
  [15:0] QUEUE_H_PTRk — Queue &lt;k&gt; (where k = 0 to 63).
0xE00 MII_G_RT_QUEUE_PEEKm ro — Queue Peek<m> Offset = E00h + (m * 4h); where m = 0h to Fh
  [15:0] QUEUE_H_PEEK_PTRm — Queue &lt;m&gt; Peek portal (where m = 0 to 15).
0xE40 MII_G_RT_QUEUE_CNTk ro — Queue Count<k> Offset = E40h + (k * 4h); where k = 0h to 3Fh
  [15:0] QUEUE_CNT_ENTRIESk — Queue Entry Count&lt;k&gt; (where k = 0 to 63).
0xF40 MII_G_RT_QUEUE_RESET access per field — Queue Reset
  [5:0] RESET_QUEUE_ID rw
